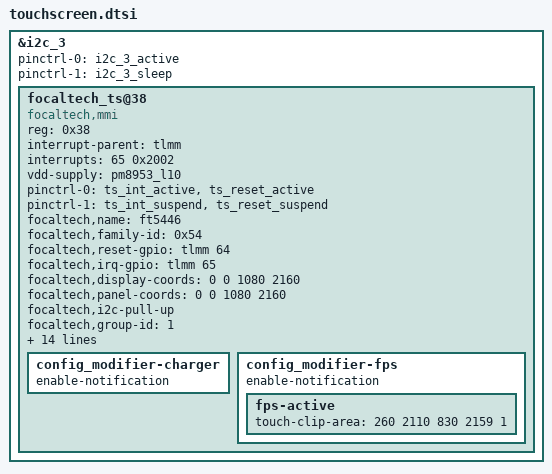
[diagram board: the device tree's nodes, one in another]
/* Copyright (c) 2018, Motorola Mobility Inc. All rights reserved.
 *
 * This program is free software; you can redistribute it and/or modify
 * it under the terms of the GNU General Public License version 2 and
 * only version 2 as published by the Free Software Foundation.
 *
 * This program is distributed in the hope that it will be useful,
 * but WITHOUT ANY WARRANTY; without even the implied warranty of
 * MERCHANTABILITY or FITNESS FOR A PARTICULAR PURPOSE.  See the
 * GNU General Public License for more details.
 */

&i2c_3 {
	status = "okay";
	pinctrl-names = "i2c_active", "i2c_sleep";
	pinctrl-0 = <&i2c_3_active>;
	pinctrl-1 = <&i2c_3_sleep>;

	focaltech_ts@38 {
		compatible = "focaltech,mmi";
		reg = <0x38>;
		interrupt-parent = <&tlmm>;
		interrupts = <65 0x2002>;
		vdd-supply = <&pm8953_l10>;
		pinctrl-names = "pmx_ts_active", "pmx_ts_suspend";
		pinctrl-0 = <&ts_int_active &ts_reset_active>;
		pinctrl-1 = <&ts_int_suspend &ts_reset_suspend>;
		focaltech,name = "ft5446";
		focaltech,family-id = <0x54>;
		focaltech,reset-gpio = <&tlmm 64 0x00>;
		focaltech,irq-gpio = <&tlmm 65 0x2008>;
		focaltech,display-coords = <0 0 1080 2160>;
		focaltech,panel-coords = <0 0 1080 2160>;
		focaltech,i2c-pull-up;
		focaltech,group-id = <1>;
		focaltech,hard-reset-delay-ms = <20>;
		focaltech,soft-reset-delay-ms = <200>;
		focaltech,num-max-touches = <10>;
		focaltech,fw-delay-aa-ms = <2>;
		focaltech,fw-delay-55-ms = <2>;
		focaltech,fw-upgrade-id1 = <0x54>;
		focaltech,fw-upgrade-id2 = <0x22>;
		focaltech,fw-delay-readid-ms = <20>;
		focaltech,fw-delay-era-flsh-ms = <2000>;
		focaltech,resume-in-workqueue;
		focaltech,ignore-id-check;
		focaltech,vendor_ids = <0x01 0x02 0x04>;
		focaltech,vendor_names ="ofilm", "toptouch", "biel";
		config_modifier-names = "charger", "fps";
		config_modifier-charger {
			enable-notification;
		};
		config_modifier-fps {
			enable-notification;
			fps-active {
				touch-clip-area = <260 2110 830 2159 1>;
			};
		};
	};
};
